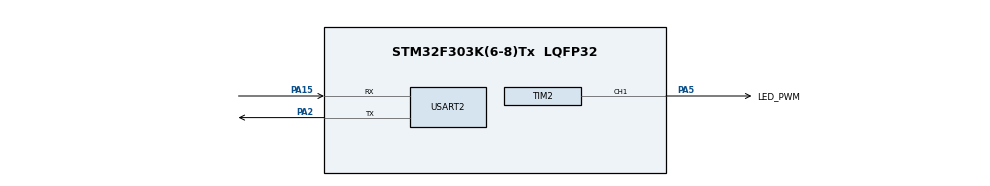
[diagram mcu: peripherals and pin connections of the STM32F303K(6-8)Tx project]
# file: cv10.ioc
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Dma.Request0=USART2_RX
Dma.Request1=USART2_TX
Dma.USART2_RX.0.Direction=DMA_PERIPH_TO_MEMORY
Dma.USART2_RX.0.Instance=DMA1_Channel6
Dma.USART2_RX.0.MemDataAlignment=DMA_MDATAALIGN_BYTE
Dma.USART2_RX.0.MemInc=DMA_MINC_ENABLE
Dma.USART2_RX.0.Mode=DMA_NORMAL
Dma.USART2_RX.0.PeriphDataAlignment=DMA_PDATAALIGN_BYTE
Dma.USART2_RX.0.PeriphInc=DMA_PINC_DISABLE
Dma.USART2_RX.0.Priority=DMA_PRIORITY_LOW
Dma.USART2_TX.1.Direction=DMA_MEMORY_TO_PERIPH
Dma.USART2_TX.1.Instance=DMA1_Channel7
Dma.USART2_TX.1.MemDataAlignment=DMA_MDATAALIGN_BYTE
Dma.USART2_TX.1.MemInc=DMA_MINC_ENABLE
Dma.USART2_TX.1.Mode=DMA_NORMAL
Dma.USART2_TX.1.PeriphDataAlignment=DMA_PDATAALIGN_BYTE
Dma.USART2_TX.1.PeriphInc=DMA_PINC_DISABLE
Dma.USART2_TX.1.Priority=DMA_PRIORITY_LOW
Mcu.Family=STM32F3
Mcu.Name=STM32F303K(6-8)Tx
Mcu.Package=LQFP32
NVIC.DMA1_Channel6_IRQn=true\:0\:0\:false\:false\:true\:false\:true
NVIC.DMA1_Channel7_IRQn=true\:0\:0\:false\:false\:true\:false\:true
NVIC.PriorityGroup=NVIC_PRIORITYGROUP_4
NVIC.TIM2_IRQn=true\:0\:0\:false\:false\:true\:true\:true
NVIC.USART2_IRQn=true\:0\:0\:false\:false\:true\:true\:true
PA15.Mode=Asynchronous
PA15.Signal=USART2_RX
PA2.Mode=Asynchronous
PA2.Signal=USART2_TX
PA5.GPIO_Label=LED_PWM
PA5.Signal=S_TIM2_CH1_ETR
ProjectManager.HeapSize=0x200
ProjectManager.StackSize=0x400
ProjectManager.TargetToolchain=STM32CubeIDE
RCC.AHBFreq_Value=8000000
RCC.APB1Freq_Value=8000000
RCC.APB2Freq_Value=8000000
RCC.CortexFreq_Value=8000000
RCC.HSE_VALUE=8000000
RCC.HSI_VALUE=8000000
RCC.SYSCLKFreq_VALUE=8000000
SH.S_TIM2_CH1_ETR.0=TIM2_CH1,PWM Generation1 CH1
TIM2.Channel-Output\ Compare2\ No\ Output=TIM_CHANNEL_2
TIM2.Channel-PWM\ Generation1\ CH1=TIM_CHANNEL_1
TIM2.Period=99
TIM2.Prescaler=799
USART2.VirtualMode-Asynchronous=VM_ASYNC
VP_TIM2_VS_ClockSourceINT.Mode=Internal
VP_TIM2_VS_no_output2.Mode=Output Compare2 No Output
board=custom

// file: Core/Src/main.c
/* USER CODE BEGIN Header */
/**
  ******************************************************************************
  * @file           : main.c
  * @brief          : Main program body
  ******************************************************************************
  * @attention
  *
  * <h2><center>&copy; Copyright (c) 2021 STMicroelectronics.
  * All rights reserved.</center></h2>
  *
  * This software component is licensed by ST under BSD 3-Clause license,
  * the "License"; You may not use this file except in compliance with the
  * License. You may obtain a copy of the License at:
  *                        opensource.org/licenses/BSD-3-Clause
  *
  ******************************************************************************
  */
/* USER CODE END Header */
#include "main.h"
#include "dma.h"
#include "tim.h"
#include "usart.h"
#include "gpio.h"

/* USER CODE BEGIN Includes */
#include "string.h"
/* USER CODE END Includes */

/* USER CODE BEGIN PTD */
typedef enum led_mode {
	MODE_AUTO,
	MODE_MANUAL
} LED_MODE;
/* USER CODE END PTD */

/* USER CODE BEGIN PV */
volatile uint8_t start_sign_received = 0;
volatile uint8_t command_buffer[10];
volatile uint8_t command_buffer_pos = 0;
volatile LED_MODE mode = MODE_AUTO;
volatile uint8_t led_target_duty = 0;
volatile uint8_t led_real_duty = 0;
volatile uint8_t direction = 0;
/* USER CODE END PV */

void SystemClock_Config(void);
/* USER CODE BEGIN PFP */
void setDutyCycle(uint8_t D);
void proccesDmaData(uint8_t sign);
void update_PWM();
/* USER CODE END PFP */

int main(void)
{

  /* MCU Configuration--------------------------------------------------------*/

  /* Reset of all peripherals, Initializes the Flash interface and the Systick. */

  LL_APB2_GRP1_EnableClock(LL_APB2_GRP1_PERIPH_SYSCFG);
  LL_APB1_GRP1_EnableClock(LL_APB1_GRP1_PERIPH_PWR);

  NVIC_SetPriorityGrouping(NVIC_PRIORITYGROUP_4);

  /* System interrupt init*/
  /* SysTick_IRQn interrupt configuration */
  NVIC_SetPriority(SysTick_IRQn, NVIC_EncodePriority(NVIC_GetPriorityGrouping(),15, 0));

  /* Configure the system clock */
  SystemClock_Config();

  /* Initialize all configured peripherals */
  MX_GPIO_Init();
  MX_DMA_Init();
  MX_USART2_UART_Init();
  MX_TIM2_Init();
  /* USER CODE BEGIN 2 */

  USART2_RegisterCallback(proccesDmaData);

  LL_TIM_CC_EnableChannel(TIM2, LL_TIM_CHANNEL_CH1);
  LL_TIM_EnableCounter(TIM2);

  TIM2CC2_register_callback(update_PWM);
  LL_TIM_CC_EnableChannel(TIM2, LL_TIM_CHANNEL_CH2);
  LL_TIM_EnableIT_CC2(TIM2);

  /* USER CODE END 2 */

  /* Infinite loop */
  while (1)
  {

  }
}

void SystemClock_Config(void)
{
  LL_FLASH_SetLatency(LL_FLASH_LATENCY_0);
  while(LL_FLASH_GetLatency()!= LL_FLASH_LATENCY_0)
  {
  }
  LL_RCC_HSI_Enable();

   /* Wait till HSI is ready */
  while(LL_RCC_HSI_IsReady() != 1)
  {

  }
  LL_RCC_HSI_SetCalibTrimming(16);
  LL_RCC_SetAHBPrescaler(LL_RCC_SYSCLK_DIV_1);
  LL_RCC_SetAPB1Prescaler(LL_RCC_APB1_DIV_1);
  LL_RCC_SetAPB2Prescaler(LL_RCC_APB2_DIV_1);
  LL_RCC_SetSysClkSource(LL_RCC_SYS_CLKSOURCE_HSI);

   /* Wait till System clock is ready */
  while(LL_RCC_GetSysClkSource() != LL_RCC_SYS_CLKSOURCE_STATUS_HSI)
  {

  }
  LL_Init1msTick(8000000);
  LL_SetSystemCoreClock(8000000);
}

/* USER CODE BEGIN 4 */
void proccesDmaData(uint8_t sign)
{
	if((sign == '\n') || (sign == '\r') || (sign == '\0'))
	{
		return;
	}

	if(!start_sign_received)
	{
		if(sign == '$')
		{
			start_sign_received = 1;
			command_buffer_pos = 0;
			return;
		}
	}
	else
	{
		if(sign == '$')
		{
			start_sign_received = 0;

			if(!strncmp(command_buffer, "manual", 6))
			{
				mode = MODE_MANUAL;
				return;
			}

			if(!strncmp(command_buffer, "auto", 4))
			{
				mode = MODE_AUTO;
				return;
			}

			if(!strncmp(command_buffer, "PWM", 3))
			{
				int8_t tens = command_buffer[3] - '0';
				int8_t ones = command_buffer[4] - '0';

				if((ones > 9) || (tens > 9) || (ones < 0) || (tens < 0))
				{
					return;
				}

				led_target_duty = tens*10 + ones;
			}
			return;
		}

		command_buffer[command_buffer_pos] = sign;
		command_buffer_pos++;
	}
}

void setDutyCycle(uint8_t D)
{
	uint8_t pulse_length;
	pulse_length = ((TIM2->ARR) * D) / 100;
	TIM2->CCR1 = pulse_length;
}

void update_PWM()
{
	if(mode==MODE_MANUAL)
	{
		if(led_real_duty<led_target_duty)
		{
			led_real_duty++;
		}

		if(led_real_duty>led_target_duty)
		{
			led_real_duty--;
		}
	}

	if(mode==MODE_AUTO)
	{
		if(direction==0)
		{
			led_real_duty++;
			if(led_real_duty==99)
			{
				direction=1;
			}
		}

		else if(direction==1)
		{
			led_real_duty--;
			if(led_real_duty==0)
			{
				direction=0;
			}
		}
	}

	setDutyCycle(led_real_duty);
}

/* USER CODE END 4 */

void Error_Handler(void)
{
  __disable_irq();
  while (1)
  {
  }
}

/************************ (C) COPYRIGHT STMicroelectronics *****END OF FILE****/
